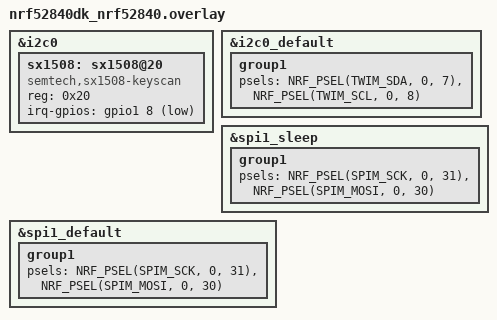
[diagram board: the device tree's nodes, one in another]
/*
 * Copyright (c) 2019 Henrik Brix Andersen <henrik@brixandersen.dk>
 *
 * SPDX-License-Identifier: Apache-2.0
 */


 &i2c0 {

    status = "okay";

	sx1508:sx1508@20 {
		compatible = "semtech,sx1508-keyscan";
		reg = <0x20>;
                /* Uncomment to use IRQ instead of polling: */
		 irq-gpios = <&gpio1 8 (GPIO_PULL_UP | GPIO_ACTIVE_LOW)>; 


	};
};

&i2c0_default {
    group1 {
        psels = <NRF_PSEL(TWIM_SDA, 0, 7)>, <NRF_PSEL(TWIM_SCL, 0, 8)>;
    };
};

&spi1_sleep {
    group1 {
        psels = <NRF_PSEL(SPIM_SCK, 0, 31)>, <NRF_PSEL(SPIM_MOSI, 0, 30)>;
    };
};

&spi1_default {
    group1 {
        psels = <NRF_PSEL(SPIM_SCK, 0, 31)>, <NRF_PSEL(SPIM_MOSI, 0, 30)>;
    };
};

